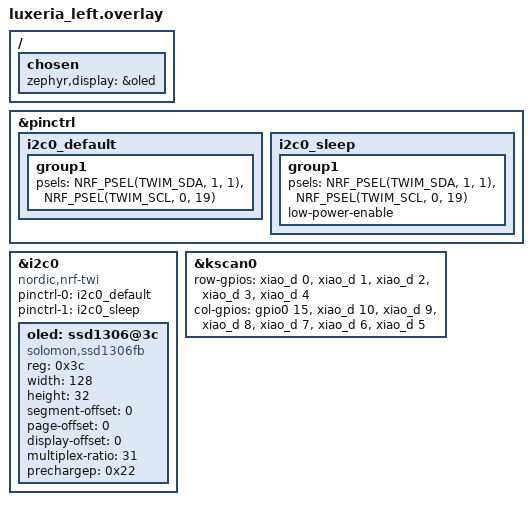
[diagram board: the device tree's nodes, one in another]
/*
 * Copyright (c) 2024 The ZMK Contributors
 * SPDX-License-Identifier: MIT
 */

#include "luxeria.dtsi"

// Seeeduino XIAO BLE pinout:
// D0  = &xiao_d 0  (P0.02)
// D1  = &xiao_d 1  (P0.03)
// D2  = &xiao_d 2  (P0.28)
// D3  = &xiao_d 3  (P0.29)
// D4  = &xiao_d 4  (P0.04)
// D5  = &xiao_d 5  (P0.05)
// D6  = &xiao_d 6  (P1.11)
// D7  = &xiao_d 7  (P1.12)
// D8  = &xiao_d 8  (P1.13)
// D9  = &xiao_d 9  (P1.14)
// D10 = &xiao_d 10 (P1.15)
// D11 = &gpio0 15  (P0.15)
// D12 = &gpio0 19  (P0.19) - OLED SCL
// D13 = &gpio1 1   (P1.01) - OLED SDA

&pinctrl {
    i2c0_default: i2c0_default {
        group1 {
            psels = <NRF_PSEL(TWIM_SDA, 1, 1)>,
                    <NRF_PSEL(TWIM_SCL, 0, 19)>;
        };
    };

    i2c0_sleep: i2c0_sleep {
        group1 {
            psels = <NRF_PSEL(TWIM_SDA, 1, 1)>,
                    <NRF_PSEL(TWIM_SCL, 0, 19)>;
            low-power-enable;
        };
    };
};

&i2c0 {
    status = "okay";
    compatible = "nordic,nrf-twi";
    pinctrl-0 = <&i2c0_default>;
    pinctrl-1 = <&i2c0_sleep>;
    pinctrl-names = "default", "sleep";

    oled: ssd1306@3c {
        compatible = "solomon,ssd1306fb";
        reg = <0x3c>;
        width = <128>;
        height = <32>;
        segment-offset = <0>;
        page-offset = <0>;
        display-offset = <0>;
        multiplex-ratio = <31>;
        prechargep = <0x22>;
    };
};

/ {
    chosen {
        zephyr,display = &oled;
    };
};

&kscan0 {
    row-gpios
        = <&xiao_d 0 (GPIO_ACTIVE_HIGH | GPIO_PULL_DOWN)>
        , <&xiao_d 1 (GPIO_ACTIVE_HIGH | GPIO_PULL_DOWN)>
        , <&xiao_d 2 (GPIO_ACTIVE_HIGH | GPIO_PULL_DOWN)>
        , <&xiao_d 3 (GPIO_ACTIVE_HIGH | GPIO_PULL_DOWN)>
        , <&xiao_d 4 (GPIO_ACTIVE_HIGH | GPIO_PULL_DOWN)>
        ;
    col-gpios
        = <&gpio0 15 GPIO_ACTIVE_HIGH>
        , <&xiao_d 10 GPIO_ACTIVE_HIGH>
        , <&xiao_d 9 GPIO_ACTIVE_HIGH>
        , <&xiao_d 8 GPIO_ACTIVE_HIGH>
        , <&xiao_d 7 GPIO_ACTIVE_HIGH>
        , <&xiao_d 6 GPIO_ACTIVE_HIGH>
        , <&xiao_d 5 GPIO_ACTIVE_HIGH>
        ;
};
